# STM32F103T6U6 register map
File version: 1.0
Registers are 32-bit, access not given, reset 0x0 unless marked. A register's access mark holds for its fields unless they carry their own. Offsets are from the block's base; [hi:lo] are bit positions; {n}, {i} and the like mark numbered series.

## USB
Base 0x40005C00
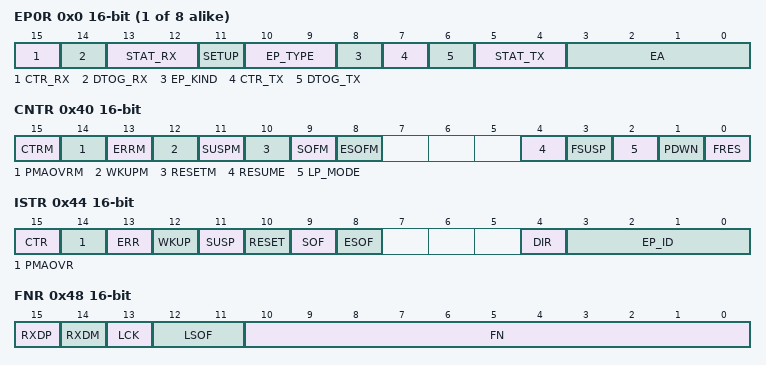
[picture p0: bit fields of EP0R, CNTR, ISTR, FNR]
{0x0+4i} EP{i}R 16-bit (i=0..7)
  [15] CTR_RX, [14] DTOG_RX, [13:12] STAT_RX, [11] SETUP, [10:9] EP_TYPE, [8] EP_KIND, [7] CTR_TX, [6] DTOG_TX, [5:4] STAT_TX, [3:0] EA
0x40 CNTR 16-bit
  [15] CTRM, [14] PMAOVRM, [13] ERRM, [12] WKUPM, [11] SUSPM, [10] RESETM, [9] SOFM, [8] ESOFM, [4] RESUME, [3] FSUSP, [2] LP_MODE, [1] PDWN, [0] FRES
0x44 ISTR 16-bit
  [15] CTR, [14] PMAOVR, [13] ERR, [12] WKUP, [11] SUSP, [10] RESET, [9] SOF, [8] ESOF, [4] DIR, [3:0] EP_ID
0x48 FNR 16-bit
  [15] RXDP, [14] RXDM, [13] LCK, [12:11] LSOF, [10:0] FN
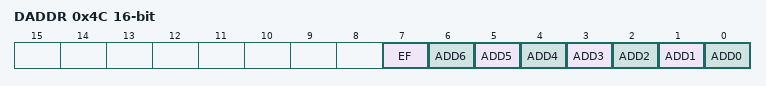
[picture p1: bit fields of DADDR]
0x4C DADDR 16-bit
  [7] EF, [n] ADD{n} (n=0..6)
0x50 BTABLE 16-bit
  [15:3] BTABLE

## BKP
Base 0x40006C00
{0x0+4i} DR{i} (i=1..10)
  [15:0] D
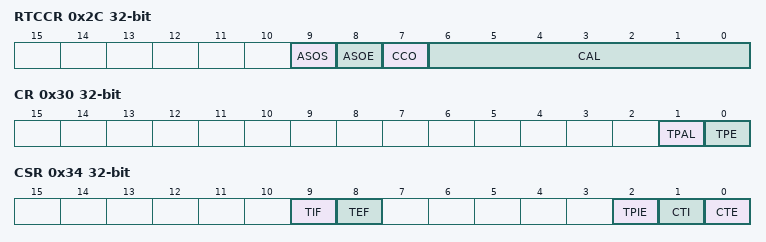
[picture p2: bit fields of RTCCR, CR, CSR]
0x2C RTCCR
  [9] ASOS, [8] ASOE, [7] CCO, [6:0] CAL
0x30 CR
  [1] TPAL, [0] TPE
0x34 CSR
  [9] TIF, [8] TEF, [2] TPIE, [1] CTI, [0] CTE

## PWR
Base 0x40007000
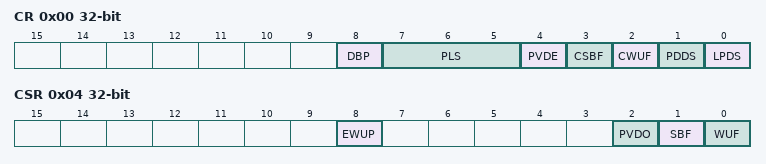
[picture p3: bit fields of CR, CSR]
0x00 CR
  [8] DBP, [7:5] PLS, [4] PVDE, [3] CSBF, [2] CWUF, [1] PDDS, [0] LPDS
0x04 CSR
  [8] EWUP, [2] PVDO, [1] SBF, [0] WUF

## AFIO
Base 0x40010000
0x00 EVCR
  [7] EVOE, [6] PORT_PE, [5] PORT_PC, [5:4] PORT_PD, [3] PIN_PX8, [2] PIN_PX4, [2:1] PIN_PX6, [3:0] PIN_PX9
0x04 MAPR
  [26] SWJ_CFG_DISABLE, [25] SWJ_CFG_JTAGDISABLE, [24] SWJ_CFG_NOJNTRST, [15] PD01_REMAP, [14] CAN_REMAP_REMAP2, [14:13] CAN_REMAP_REMAP3, [11] TIM3_REMAP_PARTIALREMAP, [11:10] TIM3_REMAP_FULLREMAP, [9] TIM2_REMAP_PARTIALREMAP2, [8] TIM2_REMAP_PARTIALREMAP1, [6] TIM1_REMAP_PARTIALREMAP, [3] USART2_REMAP, [2] USART1_REMAP, [1] I2C1_REMAP, [0] SPI1_REMAP
0x08 EXTICR.0
  [4n+2] EXTI{n}_PE (n=0..3), [4n+2:4n+1] EXTI{n}_PG (n=0..3), [4n+2:4n] EXTI{n}_PF (n=0..3)
0x0C EXTICR.1
  [4n-14] EXTI{n}_PE (n=4..7), [4n-14:4n-15] EXTI{n}_PG (n=4..7), [4n-14:4n-16] EXTI{n}_PF (n=4..7)
0x10 EXTICR.2
  [4n-30] EXTI{n}_PE (n=8..11), [4n-30:4n-31] EXTI{n}_PG (n=8..11), [4n-30:4n-32] EXTI{n}_PF (n=8..11)
0x14 EXTICR.3
  [4n-46] EXTI{n}_PE (n=12..15), [4n-46:4n-47] EXTI{n}_PG (n=12..15), [4n-46:4n-48] EXTI{n}_PF (n=12..15)
0x1C MAPR2

## EXTI
Base 0x40010400
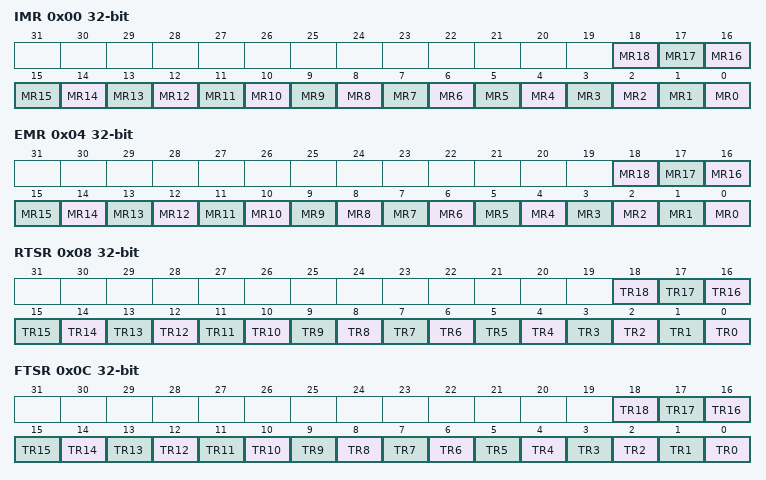
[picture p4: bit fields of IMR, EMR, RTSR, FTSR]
0x00 IMR
  [n] MR{n} (n=0..18)
0x04 EMR
  [n] MR{n} (n=0..18)
0x08 RTSR
  [n] TR{n} (n=0..18)
0x0C FTSR
  [n] TR{n} (n=0..18)
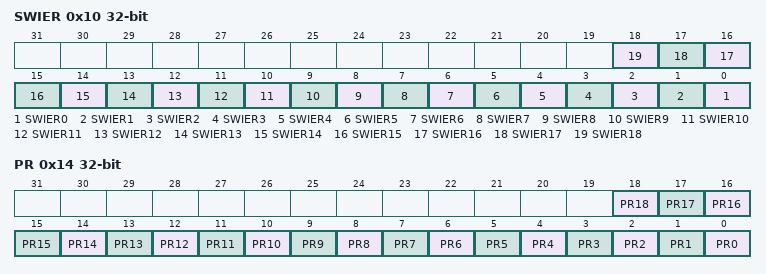
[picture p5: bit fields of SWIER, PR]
0x10 SWIER
  [n] SWIER{n} (n=0..18)
0x14 PR
  [n] PR{n} (n=0..18)

## GPIOA
Base 0x40010800
Same registers: GPIOB 0x40010C00, GPIOC 0x40011000, GPIOD 0x40011400
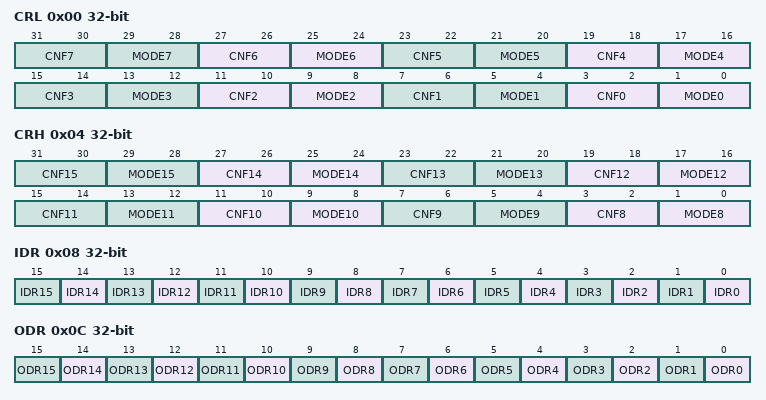
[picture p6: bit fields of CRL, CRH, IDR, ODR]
0x00 CRL
  [4n+3:4n+2] CNF{n} (n=0..7), [4n+1:4n] MODE{n} (n=0..7)
0x04 CRH
  [4n-29:4n-30] CNF{n} (n=8..15), [4n-31:4n-32] MODE{n} (n=8..15)
0x08 IDR
  [n] IDR{n} (n=0..15)
0x0C ODR
  [n] ODR{n} (n=0..15)
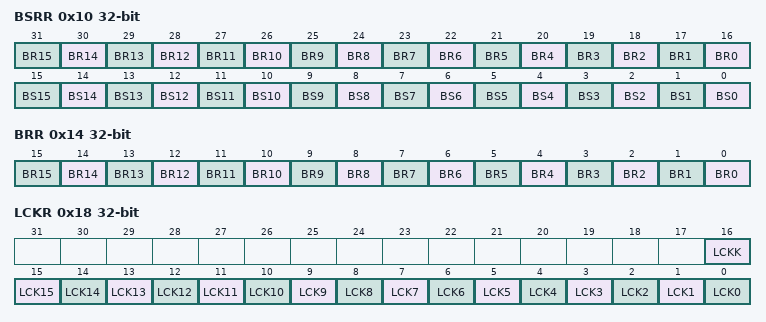
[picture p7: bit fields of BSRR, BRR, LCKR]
0x10 BSRR
  [n+16] BR{n} (n=0..15), [n] BS{n} (n=0..15)
0x14 BRR
  [n] BR{n} (n=0..15)
0x18 LCKR
  [16] LCKK, [n] LCK{n} (n=0..15)

## ADC1
Base 0x40012400
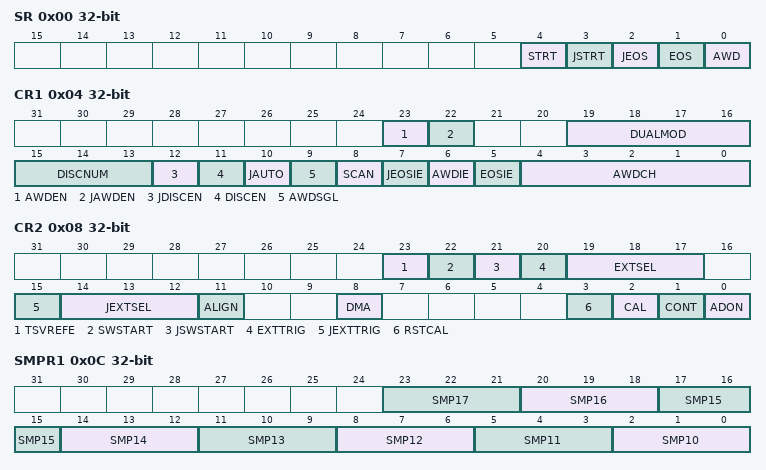
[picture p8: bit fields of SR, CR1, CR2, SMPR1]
0x00 SR
  [4] STRT, [3] JSTRT, [2] JEOS, [1] EOS, [0] AWD
0x04 CR1
  [23] AWDEN, [22] JAWDEN, [19:16] DUALMOD, [15:13] DISCNUM, [12] JDISCEN, [11] DISCEN, [10] JAUTO, [9] AWDSGL, [8] SCAN, [7] JEOSIE, [6] AWDIE, [5] EOSIE, [4:0] AWDCH
0x08 CR2
  [23] TSVREFE, [22] SWSTART, [21] JSWSTART, [20] EXTTRIG, [19:17] EXTSEL, [15] JEXTTRIG, [14:12] JEXTSEL, [11] ALIGN, [8] DMA, [3] RSTCAL, [2] CAL, [1] CONT, [0] ADON
0x0C SMPR1
  [3n-28:3n-30] SMP{n} (n=10..17)
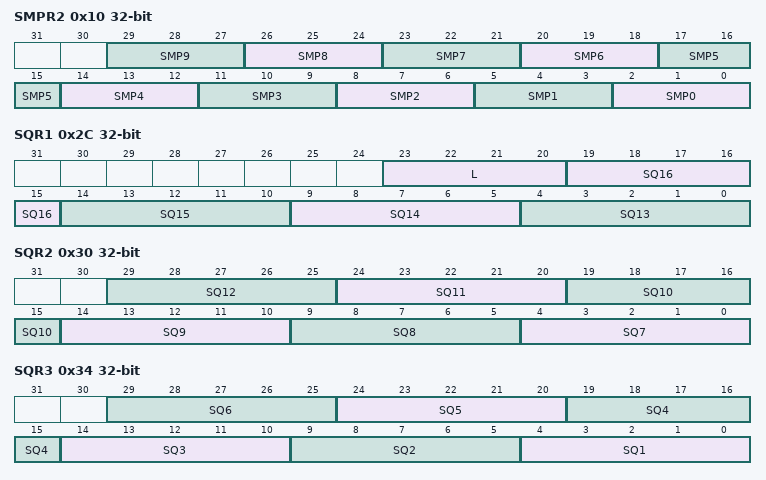
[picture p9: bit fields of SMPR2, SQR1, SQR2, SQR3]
0x10 SMPR2
  [3n+2:3n] SMP{n} (n=0..9)
{0x10+4i} JOFR{i} (i=1..4)
  [11:0] JOFFSET{i}
0x24 HTR
  [11:0] HT
0x28 LTR
  [11:0] LT
0x2C SQR1
  [23:20] L, [5n-61:5n-65] SQ{n} (n=13..16)
0x30 SQR2
  [5n-31:5n-35] SQ{n} (n=7..12)
0x34 SQR3
  [5n-1:5n-5] SQ{n} (n=1..6)
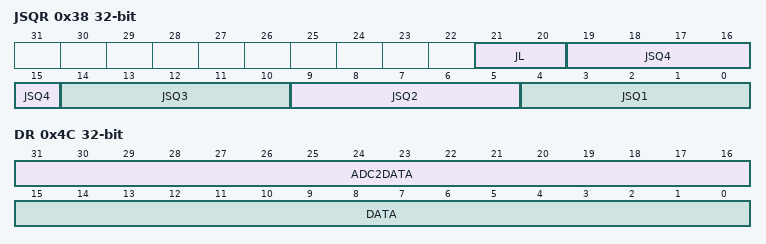
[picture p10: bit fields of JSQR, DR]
0x38 JSQR
  [21:20] JL, [5n-1:5n-5] JSQ{n} (n=1..4)
{0x38+4i} JDR{i} (i=1..4)
  [15:0] JDATA
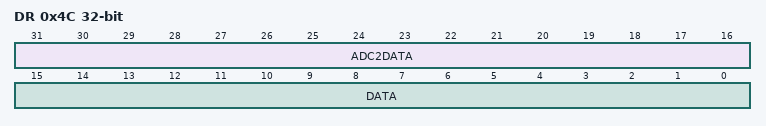
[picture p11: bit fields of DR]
0x4C DR
  [31:16] ADC2DATA, [15:0] DATA

## ADC12_COMMON
Base 0x40012400
Registers as ADC1, without SMPR1, SMPR2, JOFR{n} (n=1..4), HTR, LTR, SQR{n} (n=1..3), JSQR, JDR{n} (n=1..4).

## ADC2
Base 0x40012800
Registers as ADC1; these are added or differ:
0x4C DR
  [31:16] ADC2DATA, [15:0] DATA
